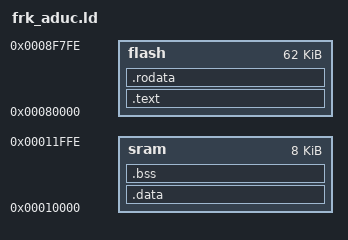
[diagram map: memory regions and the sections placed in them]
/*
 *  TOPPERS/JSP Kernel
 *      Toyohashi Open Platform for Embedded Real-Time Systems/
 *      Just Standard Profile Kernel
 * 
 *  Copyright (C) 2000-2006 by Embedded and Real-Time Systems Laboratory
 *                              Toyohashi Univ. of Technology, JAPAN
 *  Copyright (C) 2005-2006 by Logic Research Co., Ltd.
 * 
 *  上記著作権者は，以下の (1)～(4) の条件か，Free Software Foundation 
 *  によって公表されている GNU General Public License の Version 2 に記
 *  述されている条件を満たす場合に限り，本ソフトウェア（本ソフトウェア
 *  を改変したものを含む．以下同じ）を使用・複製・改変・再配布（以下，
 *  利用と呼ぶ）することを無償で許諾する．
 *  (1) 本ソフトウェアをソースコードの形で利用する場合には，上記の著作
 *      権表示，この利用条件および下記の無保証規定が，そのままの形でソー
 *      スコード中に含まれていること．
 *  (2) 本ソフトウェアを，ライブラリ形式など，他のソフトウェア開発に使
 *      用できる形で再配布する場合には，再配布に伴うドキュメント（利用
 *      者マニュアルなど）に，上記の著作権表示，この利用条件および下記
 *      の無保証規定を掲載すること．
 *  (3) 本ソフトウェアを，機器に組み込むなど，他のソフトウェア開発に使
 *      用できない形で再配布する場合には，次のいずれかの条件を満たすこ
 *      と．
 *    (a) 再配布に伴うドキュメント（利用者マニュアルなど）に，上記の著
 *        作権表示，この利用条件および下記の無保証規定を掲載すること．
 *    (b) 再配布の形態を，別に定める方法によって，TOPPERSプロジェクトに
 *        報告すること．
 *  (4) 本ソフトウェアの利用により直接的または間接的に生じるいかなる損
 *      害からも，上記著作権者およびTOPPERSプロジェクトを免責すること．
 * 
 *  本ソフトウェアは，無保証で提供されているものである．上記著作権者お
 *  よびTOPPERSプロジェクトは，本ソフトウェアに関して，その適用可能性も
 *  含めて，いかなる保証も行わない．また，本ソフトウェアの利用により直
 *  接的または間接的に生じたいかなる損害に関しても，その責任を負わない．
 * 
 */

/*
 *  FRK_ADuC
 */

OUTPUT_FORMAT("elf32-littlearm", "elf32-bigarm","elf32-littlearm") 
OUTPUT_ARCH(arm)
STARTUP(start.o);

PROVIDE(hardware_init_hook = 0);
PROVIDE(software_init_hook = 0);
PROVIDE(software_term_hook = 0);

MEMORY
{
	flash : ORIGIN = 0x00080000, LENGTH = 0x0000F7FF
	sram : ORIGIN = 0x00010000, LENGTH = 0x00001FFF
}

SECTIONS
{
    .text :
    {
        __text = . ; 	
        start.o(.vector)
	    start.o(.text)
        *(.text)
        *(.glue_7t)
        *(.glue_7)
    } > flash
    _etext = .	;
    PROVIDE (etext = .)	;
    .rodata : { 
		*(.rodata)
		*(.rodata.str1.4)
	} > flash


    . = ALIGN(4);
    __idata_start = . ;
    .data   :  AT(__idata_start) 
    {
        __data_start = . ;
        *(.data.vctsram)
        *(.data)
    } > sram
    __idata_end = __idata_start + SIZEOF(.data);
    _edata  =  . ;
    PROVIDE (edata = .);
    . = ALIGN(4);
    __bss_start = .	;		
    .bss       :
    {
      *(.bss)
      *(COMMON)
   . = ALIGN(32 / 8);
    } > sram

   . = ALIGN(32 / 8);
     _end = .		;
    __bss_end = .;
    PROVIDE (end = .)	;
    .comment 0 : { *(.comment) }

  /* DWARF debug sections.
     Symbols in the DWARF debugging sections are relative to 
     the beginning of the section so we begin them at 0.  */

  /* DWARF 1 */
  .debug          0 : { *(.debug) }
  .line           0 : { *(.line) }

  /* GNU DWARF 1 extensions */
  .debug_srcinfo  0 : { *(.debug_srcinfo) }
  .debug_sfnames  0 : { *(.debug_sfnames) }

  /* DWARF 1.1 and DWARF 2 */
  .debug_aranges  0 : { *(.debug_aranges) }
  .debug_pubnames 0 : { *(.debug_pubnames) }

  /* DWARF 2 */
  .debug_info     : { *(.debug_info) }
  .debug_abbrev   0 : { *(.debug_abbrev) }
  .debug_line     0 : { *(.debug_line) }
  .debug_frame    0 : { *(.debug_frame) }
  .debug_str      0 : { *(.debug_str) }
  .debug_loc      0 : { *(.debug_loc) }
  .debug_macinfo  0 : { *(.debug_macinfo) }

  /* SGI/MIPS DWARF 2 extensions */
  .debug_weaknames 0 : { *(.debug_weaknames) }
  .debug_funcnames 0 : { *(.debug_funcnames) }
  .debug_typenames 0 : { *(.debug_typenames) }
  .debug_varnames  0 : { *(.debug_varnames) }
}	

